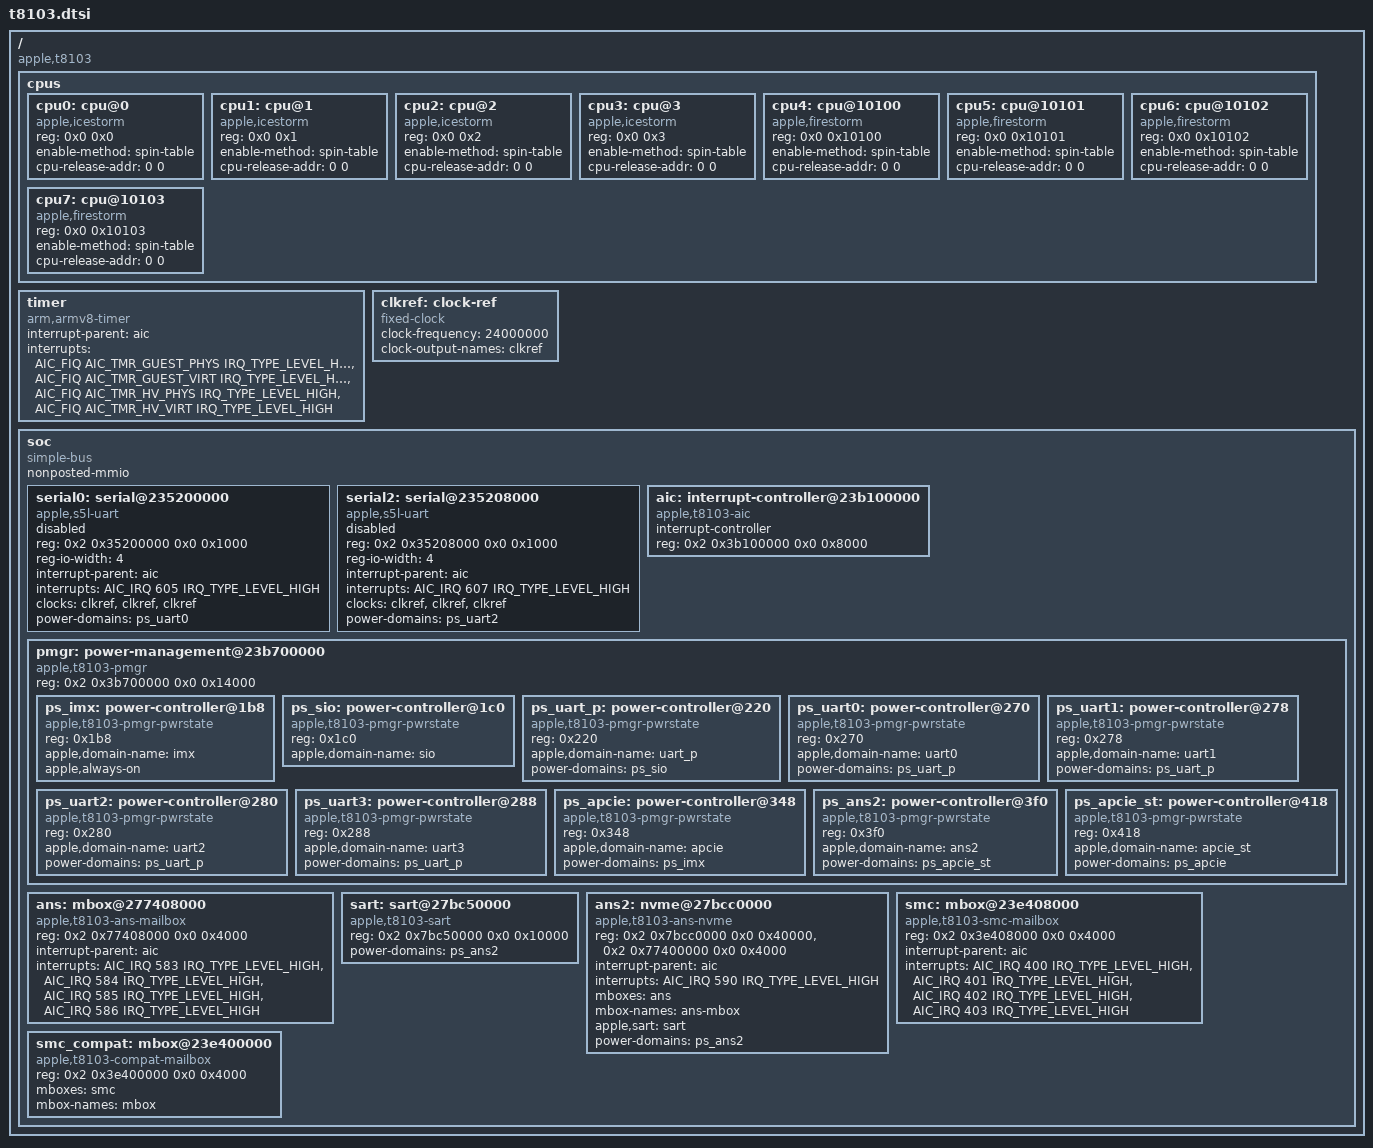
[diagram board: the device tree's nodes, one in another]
// SPDX-License-Identifier: GPL-2.0+ OR MIT
/*
 * Apple T8103 "M1" SoC
 *
 * Other names: H13G, "Tonga"
 *
 * Copyright The Asahi Linux Contributors
 */

#include <dt-bindings/interrupt-controller/apple-aic.h>
#include <dt-bindings/interrupt-controller/irq.h>

/ {
	compatible = "apple,t8103", "apple,arm-platform";

	#address-cells = <2>;
	#size-cells = <2>;

	cpus {
		#address-cells = <2>;
		#size-cells = <0>;

		cpu0: cpu@0 {
			compatible = "apple,icestorm";
			device_type = "cpu";
			reg = <0x0 0x0>;
			enable-method = "spin-table";
			cpu-release-addr = <0 0>; /* To be filled by loader */
		};

		cpu1: cpu@1 {
			compatible = "apple,icestorm";
			device_type = "cpu";
			reg = <0x0 0x1>;
			enable-method = "spin-table";
			cpu-release-addr = <0 0>; /* To be filled by loader */
		};

		cpu2: cpu@2 {
			compatible = "apple,icestorm";
			device_type = "cpu";
			reg = <0x0 0x2>;
			enable-method = "spin-table";
			cpu-release-addr = <0 0>; /* To be filled by loader */
		};

		cpu3: cpu@3 {
			compatible = "apple,icestorm";
			device_type = "cpu";
			reg = <0x0 0x3>;
			enable-method = "spin-table";
			cpu-release-addr = <0 0>; /* To be filled by loader */
		};

		cpu4: cpu@10100 {
			compatible = "apple,firestorm";
			device_type = "cpu";
			reg = <0x0 0x10100>;
			enable-method = "spin-table";
			cpu-release-addr = <0 0>; /* To be filled by loader */
		};

		cpu5: cpu@10101 {
			compatible = "apple,firestorm";
			device_type = "cpu";
			reg = <0x0 0x10101>;
			enable-method = "spin-table";
			cpu-release-addr = <0 0>; /* To be filled by loader */
		};

		cpu6: cpu@10102 {
			compatible = "apple,firestorm";
			device_type = "cpu";
			reg = <0x0 0x10102>;
			enable-method = "spin-table";
			cpu-release-addr = <0 0>; /* To be filled by loader */
		};

		cpu7: cpu@10103 {
			compatible = "apple,firestorm";
			device_type = "cpu";
			reg = <0x0 0x10103>;
			enable-method = "spin-table";
			cpu-release-addr = <0 0>; /* To be filled by loader */
		};
	};

	timer {
		compatible = "arm,armv8-timer";
		interrupt-parent = <&aic>;
		interrupt-names = "phys", "virt", "hyp-phys", "hyp-virt";
		interrupts = <AIC_FIQ AIC_TMR_GUEST_PHYS IRQ_TYPE_LEVEL_HIGH>,
			     <AIC_FIQ AIC_TMR_GUEST_VIRT IRQ_TYPE_LEVEL_HIGH>,
			     <AIC_FIQ AIC_TMR_HV_PHYS IRQ_TYPE_LEVEL_HIGH>,
			     <AIC_FIQ AIC_TMR_HV_VIRT IRQ_TYPE_LEVEL_HIGH>;
	};

	clkref: clock-ref {
		compatible = "fixed-clock";
		#clock-cells = <0>;
		clock-frequency = <24000000>;
		clock-output-names = "clkref";
	};

	soc {
		compatible = "simple-bus";
		#address-cells = <2>;
		#size-cells = <2>;

		ranges;
		nonposted-mmio;

		serial0: serial@235200000 {
			compatible = "apple,s5l-uart";
			reg = <0x2 0x35200000 0x0 0x1000>;
			reg-io-width = <4>;
			interrupt-parent = <&aic>;
			interrupts = <AIC_IRQ 605 IRQ_TYPE_LEVEL_HIGH>;
			clocks = <&clkref>, <&clkref>, <&clkref>;
			clock-names = "uart", "clk_uart_baud0", "clk_uart_baud1";
			power-domains = <&ps_uart0>;
			status = "disabled";
		};

		serial2: serial@235208000 {
			compatible = "apple,s5l-uart";
			reg = <0x2 0x35208000 0x0 0x1000>;
			reg-io-width = <4>;
			interrupt-parent = <&aic>;
			interrupts = <AIC_IRQ 607 IRQ_TYPE_LEVEL_HIGH>;
			clocks = <&clkref>, <&clkref>, <&clkref>;
			clock-names = "uart", "clk_uart_baud0", "clk_uart_baud1";
			power-domains = <&ps_uart2>;
			status = "disabled";
		};

		aic: interrupt-controller@23b100000 {
			compatible = "apple,t8103-aic", "apple,aic";
			#interrupt-cells = <3>;
			interrupt-controller;
			reg = <0x2 0x3b100000 0x0 0x8000>;
		};

		pmgr: power-management@23b700000 {
			compatible = "apple,t8103-pmgr", "apple,pmgr", "syscon", "simple-mfd";
			#address-cells = <1>;
			#size-cells = <0>;

			reg = <0x2 0x3b700000 0x0 0x14000>;

			ps_imx: power-controller@1b8 {
				compatible = "apple,t8103-pmgr-pwrstate", "apple,pmgr-pwrstate";
				reg = <0x1b8>;
				#power-domain-cells = <0>;
				#reset-cells = <0>;
				apple,domain-name = "imx";
				apple,always-on;
			};

			ps_sio: power-controller@1c0 {
				compatible = "apple,t8103-pmgr-pwrstate", "apple,pmgr-pwrstate";
				reg = <0x1c0>;
				#power-domain-cells = <0>;
				#reset-cells = <0>;
				apple,domain-name = "sio";
			};

			ps_uart_p: power-controller@220 {
				compatible = "apple,t8103-pmgr-pwrstate", "apple,pmgr-pwrstate";
				reg = <0x220>;
				#power-domain-cells = <0>;
				#reset-cells = <0>;
				apple,domain-name = "uart_p";
				power-domains = <&ps_sio>;
			};

			ps_uart0: power-controller@270 {
				compatible = "apple,t8103-pmgr-pwrstate", "apple,pmgr-pwrstate";
				reg = <0x270>;
				#power-domain-cells = <0>;
				#reset-cells = <0>;
				apple,domain-name = "uart0";
				power-domains = <&ps_uart_p>;
			};

			ps_uart1: power-controller@278 {
				compatible = "apple,t8103-pmgr-pwrstate", "apple,pmgr-pwrstate";
				reg = <0x278>;
				#power-domain-cells = <0>;
				#reset-cells = <0>;
				apple,domain-name = "uart1";
				power-domains = <&ps_uart_p>;
			};

			ps_uart2: power-controller@280 {
				compatible = "apple,t8103-pmgr-pwrstate", "apple,pmgr-pwrstate";
				reg = <0x280>;
				#power-domain-cells = <0>;
				#reset-cells = <0>;
				apple,domain-name = "uart2";
				power-domains = <&ps_uart_p>;
			};

			ps_uart3: power-controller@288 {
				compatible = "apple,t8103-pmgr-pwrstate", "apple,pmgr-pwrstate";
				reg = <0x288>;
				#power-domain-cells = <0>;
				#reset-cells = <0>;
				apple,domain-name = "uart3";
				power-domains = <&ps_uart_p>;
			};

			ps_apcie: power-controller@348 {
				compatible = "apple,t8103-pmgr-pwrstate", "apple,pmgr-pwrstate";
				reg = <0x348>;
				#power-domain-cells = <0>;
				#reset-cells = <0>;
				apple,domain-name = "apcie";
				power-domains = <&ps_imx>;
			};

			ps_ans2: power-controller@3f0 {
				compatible = "apple,t8103-pmgr-pwrstate", "apple,pmgr-pwrstate";
				reg = <0x3f0>;
				#power-domain-cells = <0>;
				#reset-cells = <0>;
				apple,domain-name = "ans2";
				power-domains = <&ps_apcie_st>;
			};

			ps_apcie_st: power-controller@418 {
				compatible = "apple,t8103-pmgr-pwrstate", "apple,pmgr-pwrstate";
				reg = <0x418>;
				#power-domain-cells = <0>;
				#reset-cells = <0>;
				apple,domain-name = "apcie_st";
				power-domains = <&ps_apcie>;
			};
		};

		ans: mbox@277408000 {
			compatible = "apple,t8103-ans-mailbox",
				"apple,t8103-asc-mailbox";
			reg = <0x2 0x77408000 0x0 0x4000>;
			interrupt-parent = <&aic>;
			interrupts = <AIC_IRQ 583 IRQ_TYPE_LEVEL_HIGH>,
				<AIC_IRQ 584 IRQ_TYPE_LEVEL_HIGH>,
				<AIC_IRQ 585 IRQ_TYPE_LEVEL_HIGH>,
				<AIC_IRQ 586 IRQ_TYPE_LEVEL_HIGH>;
			interrupt-names = "send-empty", "send-not-empty",
				"recv-empty", "recv-not-empty";
			#mbox-cells = <0>;
		};

		sart: sart@27bc50000 {
			compatible = "apple,t8103-sart";
			reg = <0x2 0x7bc50000 0x0 0x10000>;
			power-domains = <&ps_ans2>;
		};

		ans2: nvme@27bcc0000 {
			compatible = "apple,t8103-ans-nvme";
			reg = <0x2 0x7bcc0000 0x0 0x40000>, <0x2 0x77400000 0x0 0x4000>;
			reg-names = "nvme", "coproc";
			interrupt-parent = <&aic>;
			interrupts = <AIC_IRQ 590 IRQ_TYPE_LEVEL_HIGH>;
			mboxes = <&ans>;
			mbox-names = "ans-mbox";
			apple,sart = <&sart>;
			power-domains = <&ps_ans2>;
		 };

		smc: mbox@23e408000 {
			compatible = "apple,t8103-smc-mailbox",
				"apple,t8103-asc-mailbox";
			reg = <0x2 0x3e408000 0x0 0x4000>;
			interrupt-parent = <&aic>;
			interrupts = <AIC_IRQ 400 IRQ_TYPE_LEVEL_HIGH>,
				<AIC_IRQ 401 IRQ_TYPE_LEVEL_HIGH>,
				<AIC_IRQ 402 IRQ_TYPE_LEVEL_HIGH>,
				<AIC_IRQ 403 IRQ_TYPE_LEVEL_HIGH>;
			interrupt-names = "send-empty", "send-not-empty",
				"recv-empty", "recv-not-empty";
			#mbox-cells = <0>;
		};

		smc_compat: mbox@23e400000 {
			compatible = "apple,t8103-compat-mailbox";
			reg-names = "coproc";
			reg = <0x2 0x3e400000 0x0 0x4000>;
			mboxes = <&smc>;
			mbox-names = "mbox";
			#mbox-cells = <1>;
		};
	};
};
